VERSION "1.0"

NS_ :

BS_:

BU_: GATEWAY SBW_ECU

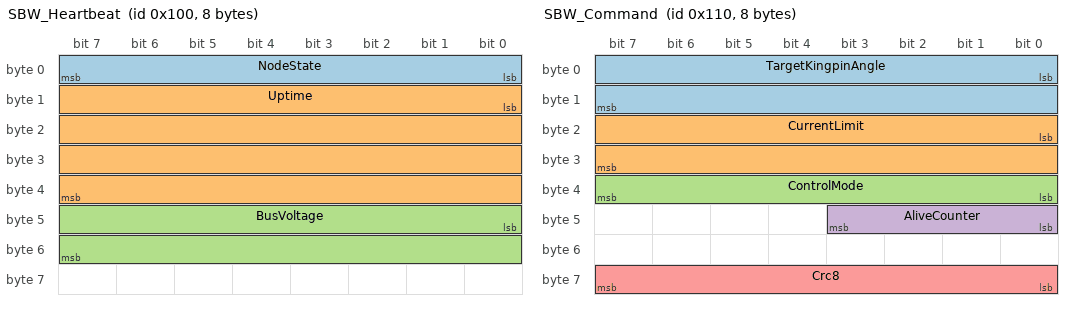
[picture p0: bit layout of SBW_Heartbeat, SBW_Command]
BO_ 256 SBW_Heartbeat: 8 SBW_ECU
 SG_ NodeState : 0|8@1+ (1,0) [0|2] "" GATEWAY
 SG_ Uptime : 8|32@1+ (0.001,0) [0|4294967.295] "s" GATEWAY
 SG_ BusVoltage : 40|16@1+ (0.001,0) [0|65.535] "V" GATEWAY

BO_ 272 SBW_Command: 8 GATEWAY
 SG_ TargetKingpinAngle : 0|16@1- (0.001,0) [-0.524|0.524] "rad" SBW_ECU
 SG_ CurrentLimit : 16|16@1+ (0.001,0) [0|2.5] "A" SBW_ECU
 SG_ ControlMode : 32|8@1+ (1,0) [0|4] "" SBW_ECU
 SG_ AliveCounter : 40|4@1+ (1,0) [0|15] "" SBW_ECU
 SG_ Crc8 : 56|8@1+ (1,0) [0|255] "" SBW_ECU

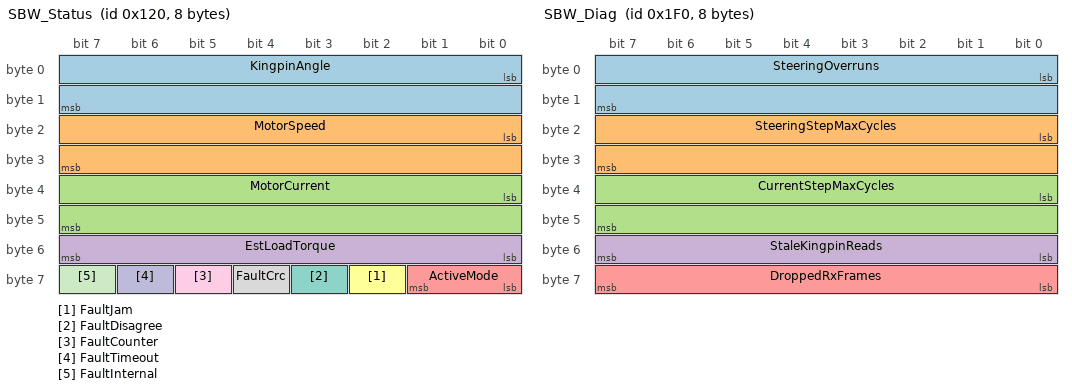
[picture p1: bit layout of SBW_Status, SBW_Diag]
BO_ 288 SBW_Status: 8 SBW_ECU
 SG_ KingpinAngle : 0|16@1- (0.001,0) [-32.768|32.767] "rad" GATEWAY
 SG_ MotorSpeed : 16|16@1- (0.1,0) [-3276.8|3276.7] "rad/s" GATEWAY
 SG_ MotorCurrent : 32|16@1- (0.001,0) [-32.768|32.767] "A" GATEWAY
 SG_ EstLoadTorque : 48|8@1- (0.001,0) [-0.128|0.127] "N.m" GATEWAY
 SG_ ActiveMode : 56|2@1+ (1,0) [0|3] "" GATEWAY
 SG_ FaultJam : 58|1@1+ (1,0) [0|1] "" GATEWAY
 SG_ FaultDisagree : 59|1@1+ (1,0) [0|1] "" GATEWAY
 SG_ FaultCrc : 60|1@1+ (1,0) [0|1] "" GATEWAY
 SG_ FaultCounter : 61|1@1+ (1,0) [0|1] "" GATEWAY
 SG_ FaultTimeout : 62|1@1+ (1,0) [0|1] "" GATEWAY
 SG_ FaultInternal : 63|1@1+ (1,0) [0|1] "" GATEWAY

BO_ 496 SBW_Diag: 8 SBW_ECU
 SG_ SteeringOverruns : 0|16@1+ (1,0) [0|65535] "" GATEWAY
 SG_ SteeringStepMaxCycles : 16|16@1+ (1,0) [0|65535] "" GATEWAY
 SG_ CurrentStepMaxCycles : 32|16@1+ (1,0) [0|65535] "" GATEWAY
 SG_ StaleKingpinReads : 48|8@1+ (1,0) [0|255] "" GATEWAY
 SG_ DroppedRxFrames : 56|8@1+ (1,0) [0|255] "" GATEWAY

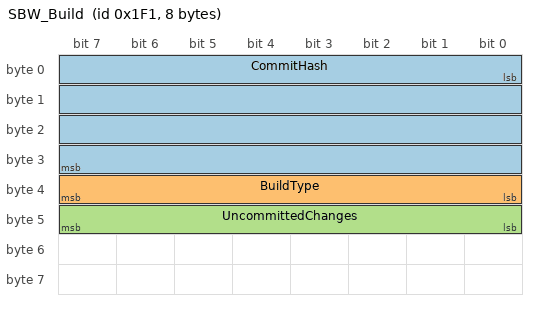
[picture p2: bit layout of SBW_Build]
BO_ 497 SBW_Build: 8 SBW_ECU
 SG_ CommitHash : 0|32@1+ (1,0) [0|4294967295] "" GATEWAY
 SG_ BuildType : 32|8@1+ (1,0) [0|1] "" GATEWAY
 SG_ UncommittedChanges : 40|8@1+ (1,0) [0|1] "" GATEWAY

CM_ BO_ 272 "Steering command from the gateway, 200 Hz. Crc8 is CRC-8/SAE-J1850 (poly 0x1D, init 0xFF, xorout 0xFF) over bytes 0-6.";
CM_ BO_ 288 "Steering status from the ECU, 200 Hz, plus one extra frame in the tick a fault latches.";
CM_ BO_ 496 "Runtime diagnostics, 10 Hz: steering-step overruns, worst execution times in CPU cycles (0 in SIL), stale kingpin reads and dropped received frames. Counts saturate.";
CM_ BO_ 497 "Build identity, sent 1 ms after start-up and then every 1 s, so a test bench can confirm which firmware it is testing.";
CM_ SG_ 497 CommitHash "First 8 hex digits of the git commit the image was built from, read as one number.";
CM_ SG_ 497 UncommittedChanges "1 when tracked files differed from that commit at build time.";
CM_ SG_ 272 AliveCounter "Increments by 1 (mod 16) every frame.";
CM_ SG_ 288 FaultInternal "Kingpin sensor stale or steering step overrun; SBW_Diag tells which.";
VAL_ 256 NodeState 0 "INIT" 1 "RUNNING" 2 "FAULT" ;
VAL_ 272 ControlMode 0 "OFF" 1 "MOTOR_ONLY" 2 "KINGPIN_ONLY" 3 "DUAL_LOOP" 4 "CLEAR_FAULT" ;
VAL_ 288 ActiveMode 0 "OFF" 1 "MOTOR_ONLY" 2 "KINGPIN_ONLY" 3 "DUAL_LOOP" ;
VAL_ 497 BuildType 0 "DEBUG" 1 "RELEASE" ;
